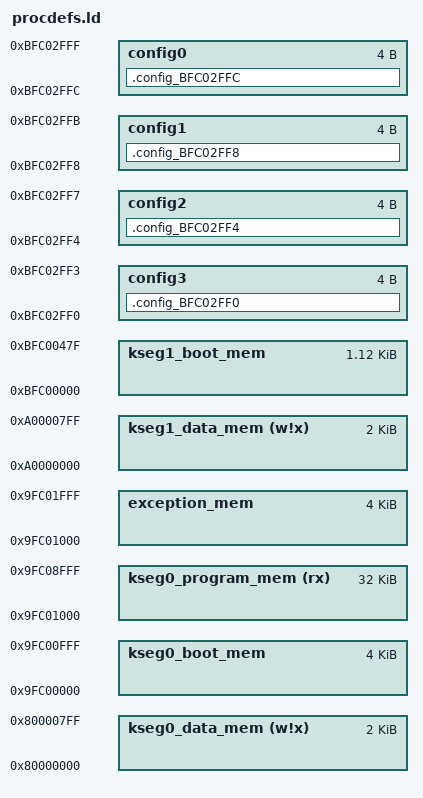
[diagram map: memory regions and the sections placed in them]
OUTPUT_FORMAT("elf32-tradlittlemips")
OUTPUT_ARCH(pic32mx)
ENTRY(_reset)

/*************************************************************************
 * Processor-specific object file.  Contains SFR definitions.
 *************************************************************************/
INPUT("processor.o")

/*************************************************************************
 * Processor-specific peripheral libraries are optional
 *************************************************************************/
OPTIONAL("libmchp_peripheral.a")
/*OPTIONAL("libmchp_peripheral_32MXGENERIC.a")*/

/*************************************************************************
 * For interrupt vector handling
 *************************************************************************/
PROVIDE(_vector_spacing = 0x00000001);
_ebase_address = 0x9FC01000;

/*************************************************************************
 * Memory Address Equates
 * _RESET_ADDR      -- Reset Vector
 * _BEV_EXCPT_ADDR  -- Boot exception Vector
 * _DBG_EXCPT_ADDR  -- In-circuit Debugging Exception Vector
 * _DBG_CODE_ADDR   -- In-circuit Debug Executive address
 * _DBG_CODE_SIZE   -- In-circuit Debug Executive size
 * _GEN_EXCPT_ADDR  -- General Exception Vector
 *************************************************************************/
_RESET_ADDR              = 0xBFC00000;
_BEV_EXCPT_ADDR          = 0xBFC00380;
_DBG_EXCPT_ADDR          = 0xBFC00480;
_DBG_CODE_ADDR           = 0xBFC02000;
_DBG_CODE_SIZE           = 0xFF0     ;
_GEN_EXCPT_ADDR          = _ebase_address + 0x180;

/*************************************************************************
 * Memory Regions
 *
 * Memory regions without attributes cannot be used for orphaned sections.
 * Only sections specifically assigned to these regions can be allocated
 * into these regions.
 *************************************************************************/
MEMORY
{
  kseg1_boot_mem             : ORIGIN = 0xBFC00000, LENGTH = 0x480
  kseg0_program_mem    (rx)  : ORIGIN = 0x9FC01000, LENGTH = 0x8000
  kseg0_boot_mem             : ORIGIN = 0x9FC00000, LENGTH = 0x1000

  exception_mem              : ORIGIN = 0x9FC01000, LENGTH = 0x1000

  config3                    : ORIGIN = 0xBFC02FF0, LENGTH = 0x4
  config2                    : ORIGIN = 0xBFC02FF4, LENGTH = 0x4
  config1                    : ORIGIN = 0xBFC02FF8, LENGTH = 0x4
  config0                    : ORIGIN = 0xBFC02FFC, LENGTH = 0x4

  kseg0_data_mem       (w!x) : ORIGIN = 0x80000000, LENGTH = 2K  
  kseg1_data_mem       (w!x) : ORIGIN = 0xA0000000, LENGTH = 2K

/*  
  kseg0_boot_mem             : ORIGIN = 0x9FC004b0, LENGTH = 0x0
  exception_mem              : ORIGIN = 0x9FC01000, LENGTH = 0x1000
  kseg1_boot_mem_4B0         : ORIGIN = 0xBFC004B0, LENGTH = 0x1000 - 0x4B0
  debug_exec_mem             : ORIGIN = 0xBFC02000, LENGTH = 0xFF0
  config3                    : ORIGIN = 0xBFC02FF0, LENGTH = 0x4
  config2                    : ORIGIN = 0xBFC02FF4, LENGTH = 0x4
  config1                    : ORIGIN = 0xBFC02FF8, LENGTH = 0x4
  config0                    : ORIGIN = 0xBFC02FFC, LENGTH = 0x4
  kseg0_data_mem       (w!x) : ORIGIN = 0x80000000, LENGTH = 0x80000  
  kseg1_data_mem       (w!x) : ORIGIN = 0xA0000000, LENGTH = 0x80000
  sfrs                       : ORIGIN = 0xBF800000, LENGTH = 0x100000*/
}

/*************************************************************************
 * Configuration-word sections
 *************************************************************************/
SECTIONS
{
  .config_BFC02FF0 : {
    KEEP(*(.config_BFC02FF0))
  } > config3
  .config_BFC02FF4 : {
    KEEP(*(.config_BFC02FF4))
  } > config2
  .config_BFC02FF8 : {
    KEEP(*(.config_BFC02FF8))
  } > config1
  .config_BFC02FFC : {
    KEEP(*(.config_BFC02FFC))
  } > config0
}

SECTIONS
{
 .reset _RESET_ADDR :
  {
    KEEP(*(.reset))
    KEEP(*(.reset.startup))
  } > kseg1_boot_mem
  .startup ORIGIN(kseg0_boot_mem) :
  {
    KEEP(*(.startup))
  } > kseg0_boot_mem
  .text :
  {
    *(.stub .gnu.linkonce.t.*)
    KEEP (*(.text.*personality*))
    *(.mips16.fn.*)
    *(.mips16.call.*)
    *(.gnu.warning)
    . = ALIGN(4) ;
  } >kseg0_program_mem
  /*
   *  Note that input sections named .data* are not mapped here.
   *  The best-fit allocator locates them, so that they may flow
   *  around absolute sections as needed.
   */
  .data   :
  {
    *( .gnu.linkonce.d.*)
    SORT(CONSTRUCTORS)
    *(.data1)
    . = ALIGN(4) ;
  } >kseg0_data_mem
  . = .;
  _gp = ALIGN(16) + 0x7ff0;
  .got ALIGN(4) :
  {
    *(.got.plt) *(.got)
    . = ALIGN(4) ;
  } >kseg0_data_mem /* AT>kseg0_program_mem */
  /*
   *  Align here to ensure that the .bss section occupies space up to
   *  _end.  Align after .bss to ensure correct alignment even if the
   *  .bss section disappears because there are no input sections.
   *
   *  Note that input sections named .bss* are no longer mapped here.
   *  The best-fit allocator locates them, so that they may flow
   *  around absolute sections as needed.
   *
   */
  .bss     :
  {
    *(.dynbss)
    *(COMMON)
   /* Align here to ensure that the .bss section occupies space up to
      _end.  Align after .bss to ensure correct alignment even if the
      .bss section disappears because there are no input sections. */
   . = ALIGN(. != 0 ? 4 : 1);
  } >kseg0_data_mem
  . = ALIGN(4) ;
  _end = . ;
  _bss_end = . ;
  _bss_begin = . ;
  .sbss ALIGN(4) :
  {
    _sbss_begin = . ;
    *(.dynsbss)
    *(.sbss .sbss.* .gnu.linkonce.sb.*)
    *(.scommon)
    _sbss_end = . ;
    . = ALIGN(4) ;
  } >kseg0_data_mem
}
